# nrf54lm20b_application register map
Vendor: Nordic Semiconductor; Series: nrf54l; File version: 1
CPU: CM33 r0p4, little endian, MPU, FPU, 3 interrupt priority bits, 270 interrupts, 4 SAU regions
Registers are 32-bit, read-write, reset 0x0 unless marked. A register's access mark holds for its fields unless they carry their own. Offsets are from the block's base; [hi:lo] are bit positions; lines under a group give offsets from that group; {n}, {i} and the like mark numbered series; 'fields as' and 'values as' point back to an identical list.

## ICACHEDATA_S — CACHEDATA
Base 0x02F00000
{0x0+0x40*i} SET[{i}] (i=0..127) group — Unspecified
  {0x0+0x20*j} WAY[{j}] (j=0..1) group — Unspecified
    {0x0+8k} DU[{k}] (k=0..3) group — Unspecified
      {0x0+4l} DATA[{l}] (l=0..1) — Description collection: Cache data bits for DATA[q] in DU[p] (DataUnit) of SET[n], WAY[o].
        [31:0] Data ro

## ICACHEINFO_S — CACHEINFO
Base 0x02F10000
{0x0+8i} SET[{i}] (i=0..127) group — Unspecified
  {0x0+4j} WAY[{j}] (j=0..1) group — Unspecified
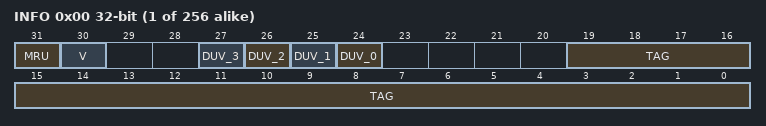
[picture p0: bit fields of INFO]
    0x00 INFO — Description cluster: Cache information for SET[n], WAY[o].
      [31] MRU ro — Most recently used way.
        0=Way0 was most recently used; 1=Way1 was most recently used
      [30] V ro — Line valid bit.
        0=Invalid cache line; 1=Valid cache line
      [n+24] DUV_{n} ro (n=0..3) — Data unit valid info.
        0=Invalid data unit; 1=Valid data unit
      [19:0] TAG ro — Cache tag.

## ICACHE_S — Cache
Base 0xE0082000
0x08 TASKS_INVALIDATECACHE wo — Invalidate the cache.
  [0] TASKS_INVALIDATECACHE
    1=Trigger task
0x14 TASKS_INVALIDATELINE wo — Invalidate the line.
  [0] TASKS_INVALIDATELINE
    1=Trigger task
0x20 TASKS_ERASE wo — Erase the cache.
  [0] TASKS_ERASE
    1=Trigger task
0x400 STATUS ro — Status of the cache activities.
  [0] READY — Ready status.
    0=Ready (Activity is done and ready for the next activity.); 1=Busy (Activity is in progress.)
0x404 ENABLE — Enable cache.
  [0] ENABLE — Enable cache
    0=Disabled (Disable cache); 1=Enabled (Enable cache)
0x410 LINEADDR — Memory address covered by the line to be maintained.
  [31:0] ADDR — Address.
0x414 PROFILING group — Unspecified
  0x00 ENABLE — Enable the profiling counters.
    [0] ENABLE — Enable the profiling counters
      0=Disable profiling; 1=Enable profiling
  0x04 CLEAR wo — Clear the profiling counters.
    [0] CLEAR — Clearing the profiling counters
      1=Clear the profiling counters
  0x08 HIT ro — The cache hit counter for cache region.
    [31:0] HITS — Number of cache hits
  0x0C MISS ro — The cache miss counter for cache region.
    [31:0] MISSES — Number of cache misses
  0x10 LMISS ro — The cache line miss counter for cache region.
    [31:0] LMISSES — Number of cache line misses
  0x14 READS ro — Number of reads for cache region.
  0x18 WRITES ro — Number of writes for cache region.
0x430 DEBUGLOCK rw-once — Lock debug mode.
  [0] DEBUGLOCK — Lock debug mode
    0=Unlocked (Debug mode unlocked); 1=Locked (Debug mode locked. Ignores any other value written.)
0x434 WRITELOCK — Lock cache updates.
  [0] WRITELOCK — Lock cache updates
    0=Unlocked (Cache updates unlocked); 1=Locked (Cache updates locked)

## SWI00_S — Software interrupt 0
Base 0x5001C000
Same registers: SWI01_S 0x5001D000, SWI02_S 0x5001E000, SWI03_S 0x5001F000

## GLOBAL_DPPIC00_NS — Distributed programmable peripheral interconnect controller 0
Base 0x40042000; alternate view of GLOBAL_USBHSCORE_NS
Same registers: GLOBAL_DPPIC10_NS 0x40082000, GLOBAL_DPPIC20_NS 0x400C2000, GLOBAL_DPPIC30_NS 0x40102000, GLOBAL_DPPIC00_S 0x50042000 (alternate view of GLOBAL_USBHSCORE_S), GLOBAL_DPPIC10_S 0x50082000, GLOBAL_DPPIC20_S 0x500C2000, GLOBAL_DPPIC30_S 0x50102000
{0x0+8i} TASKS_CHG[{i}] (i=0..5) group — Channel group tasks
  0x00 EN wo — Description cluster: Enable channel group n
    [0] EN — Enable channel group n
      1=Trigger task
  0x04 DIS wo — Description cluster: Disable channel group n
    [0] DIS — Disable channel group n
      1=Trigger task
{0x80+8i} SUBSCRIBE_CHG[{i}] (i=0..5) group — Subscribe configuration for tasks
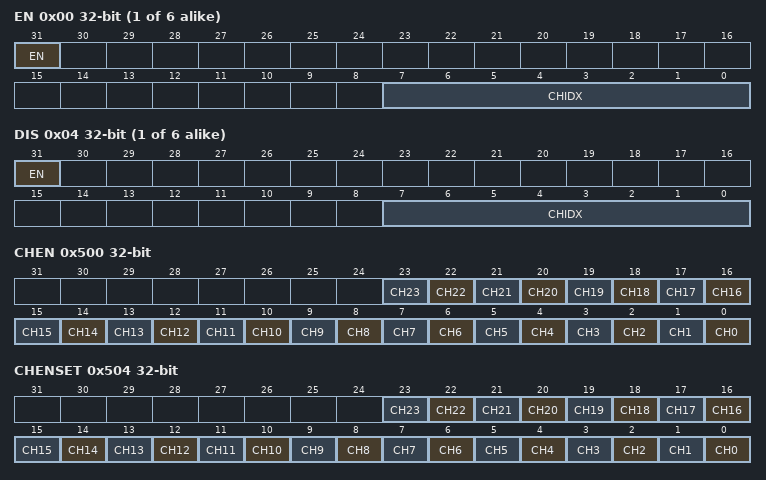
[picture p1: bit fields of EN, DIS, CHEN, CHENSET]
  0x00 EN — Description cluster: Subscribe configuration for task CHG[n].EN
    [31] EN
      0=Disabled (Disable subscription); 1=Enabled (Enable subscription)
    [7:0] CHIDX — DPPI channel that task CHG[n].EN will subscribe to
  0x04 DIS — Description cluster: Subscribe configuration for task CHG[n].DIS
    [31] EN
      values as SUBSCRIBE_CHG[0].EN.EN
    [7:0] CHIDX — DPPI channel that task CHG[n].DIS will subscribe to
0x500 CHEN — Channel enable register
  [all] fields
    0=Disabled (Disable channel); 1=Enabled (Enable channel)
  [n] CH{n} (n=0..23) — Enable or disable channel {n}
0x504 CHENSET write-1-sets — Channel enable set register
  [all] fields
    on read: 0=Disabled (Read: Channel disabled); 1=Enabled (Read: Channel enabled) | on write: 1=Set (Write: Enable channel)
  [n] CH{n} (n=0..23) — Channel {n} enable set register. Writing 0 has no effect.
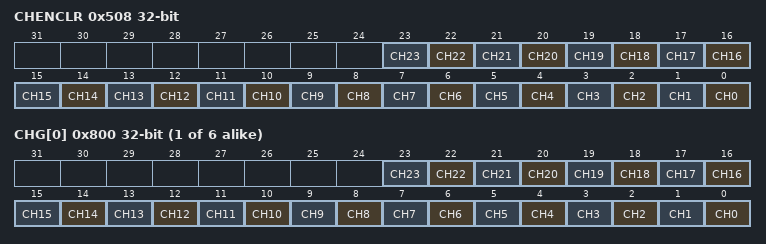
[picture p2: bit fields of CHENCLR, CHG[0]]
0x508 CHENCLR write-1-clears — Channel enable clear register
  [all] fields
    on read: 0=Disabled (Read: Channel disabled); 1=Enabled (Read: Channel enabled) | on write: 1=Clear (Write: Disable channel)
  [n] CH{n} (n=0..23) — Channel {n} enable clear register. Writing 0 has no effect.
{0x800+4i} CHG[{i}] (i=0..5) — Description collection: Channel group n Note: Writes to this register are ignored if either SUBSCRIBE_CHG[n].EN or SUBSCRIBE_CHG[n].DIS is enabled
  [all] fields
    0=Excluded; 1=Included
  [n] CH{n} (n=0..23) — Include or exclude channel {n}

## Notices in the file
Copyright (c) 2010 - 2026, Nordic Semiconductor ASA All rights reserved.
SPDX-License-Identifier: BSD-3-Clause
Redistribution and use in source and binary forms, with or without
modification, are permitted provided that the following conditions are met:
1. Redistributions of source code must retain the above copyright notice, this
list of conditions and the following disclaimer.
2. Redistributions in binary form must reproduce the above copyright
notice, this list of conditions and the following disclaimer in the
documentation and/or other materials provided with the distribution.
3. Neither the name of Nordic Semiconductor ASA nor the names of its
contributors may be used to endorse or promote products derived from this
software without specific prior written permission.
THIS SOFTWARE IS PROVIDED BY THE COPYRIGHT HOLDERS AND CONTRIBUTORS "AS IS"
AND ANY EXPRESS OR IMPLIED WARRANTIES, INCLUDING, BUT NOT LIMITED TO, THE
IMPLIED WARRANTIES OF MERCHANTABILITY, AND FITNESS FOR A PARTICULAR PURPOSE
ARE DISCLAIMED. IN NO EVENT SHALL NORDIC SEMICONDUCTOR ASA OR CONTRIBUTORS BE
LIABLE FOR ANY DIRECT, INDIRECT, INCIDENTAL, SPECIAL, EXEMPLARY, OR
CONSEQUENTIAL DAMAGES (INCLUDING, BUT NOT LIMITED TO, PROCUREMENT OF
SUBSTITUTE GOODS OR SERVICES; LOSS OF USE, DATA, OR PROFITS; OR BUSINESS
INTERRUPTION) HOWEVER CAUSED AND ON ANY THEORY OF LIABILITY, WHETHER IN
CONTRACT, STRICT LIABILITY, OR TORT (INCLUDING NEGLIGENCE OR OTHERWISE)
ARISING IN ANY WAY OUT OF THE USE OF THIS SOFTWARE, EVEN IF ADVISED OF THE
POSSIBILITY OF SUCH DAMAGE.
